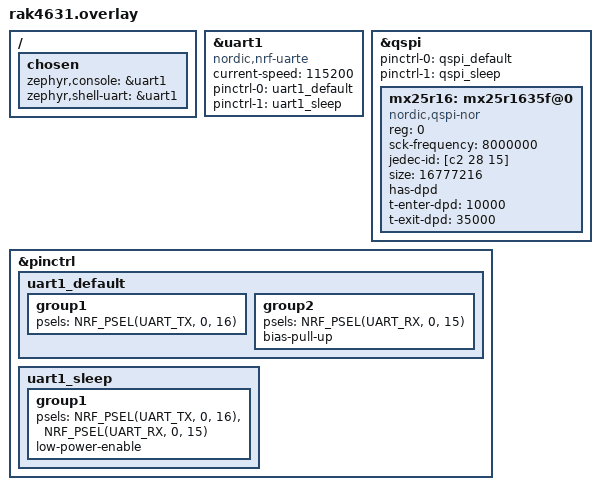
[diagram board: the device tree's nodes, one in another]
/*
 * QSPI Flash test - Node (Link)
 *
 * Console: uart1 (P0.16 TX / P0.15 RX) @ 115200 → ttyUSB0
 * QSPI: MX25R1635F (16Mbit) — RAK4631 모듈 내장
 */

/ {
	chosen {
		zephyr,console = &uart1;
		zephyr,shell-uart = &uart1;
	};
};

&uart1 {
	compatible = "nordic,nrf-uarte";
	status = "okay";
	current-speed = <115200>;
	pinctrl-0 = <&uart1_default>;
	pinctrl-1 = <&uart1_sleep>;
	pinctrl-names = "default", "sleep";
};

&qspi {
	status = "okay";
	pinctrl-0 = <&qspi_default>;
	pinctrl-1 = <&qspi_sleep>;
	pinctrl-names = "default", "sleep";

	mx25r16: mx25r1635f@0 {
		compatible = "nordic,qspi-nor";
		reg = <0>;
		sck-frequency = <8000000>;
		jedec-id = [c2 28 15];
		size = <16777216>;
		has-dpd;
		t-enter-dpd = <10000>;
		t-exit-dpd = <35000>;
	};
};

&pinctrl {
	uart1_default: uart1_default {
		group1 {
			psels = <NRF_PSEL(UART_TX, 0, 16)>;
		};
		group2 {
			psels = <NRF_PSEL(UART_RX, 0, 15)>;
			bias-pull-up;
		};
	};

	uart1_sleep: uart1_sleep {
		group1 {
			psels = <NRF_PSEL(UART_TX, 0, 16)>,
				<NRF_PSEL(UART_RX, 0, 15)>;
			low-power-enable;
		};
	};
};
